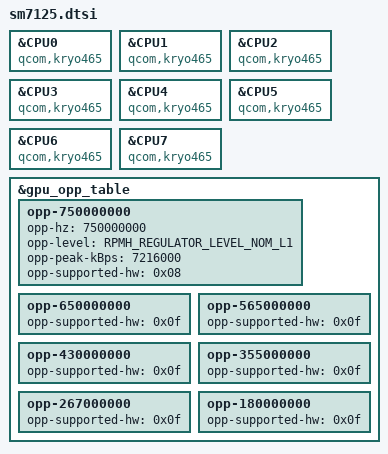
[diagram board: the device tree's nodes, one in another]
// SPDX-License-Identifier: GPL-2.0
/*
 * Copyright (c) 2021, The Linux Foundation. All rights reserved.
 */

#include "sc7180.dtsi"

/* SM7125 uses Kryo 465 instead of Kryo 468 */
&CPU0 { compatible = "qcom,kryo465"; };
&CPU1 { compatible = "qcom,kryo465"; };
&CPU2 { compatible = "qcom,kryo465"; };
&CPU3 { compatible = "qcom,kryo465"; };
&CPU4 { compatible = "qcom,kryo465"; };
&CPU5 { compatible = "qcom,kryo465"; };
&CPU6 { compatible = "qcom,kryo465"; };
&CPU7 { compatible = "qcom,kryo465"; };


/*
 * SM7125 soc have slightly slower max freq,
 * in order to exclude higher freq, introduce
 * a higher fuse-hw bit 8.
*/
&gpu_opp_table {
	opp-750000000 {
		opp-hz = /bits/ 64 <750000000>;
		opp-level = <RPMH_REGULATOR_LEVEL_NOM_L1>;
		opp-peak-kBps = <7216000>;
		opp-supported-hw = <0x08>;
	};

	opp-650000000 {
		opp-supported-hw = <0x0f>;
	};

	opp-565000000 {
		opp-supported-hw = <0x0f>;
	};

	opp-430000000 {
		opp-supported-hw = <0x0f>;
	};

	opp-355000000 {
		opp-supported-hw = <0x0f>;
	};

	opp-267000000 {
		opp-supported-hw = <0x0f>;
	};

	opp-180000000 {
		opp-supported-hw = <0x0f>;
	};
};
